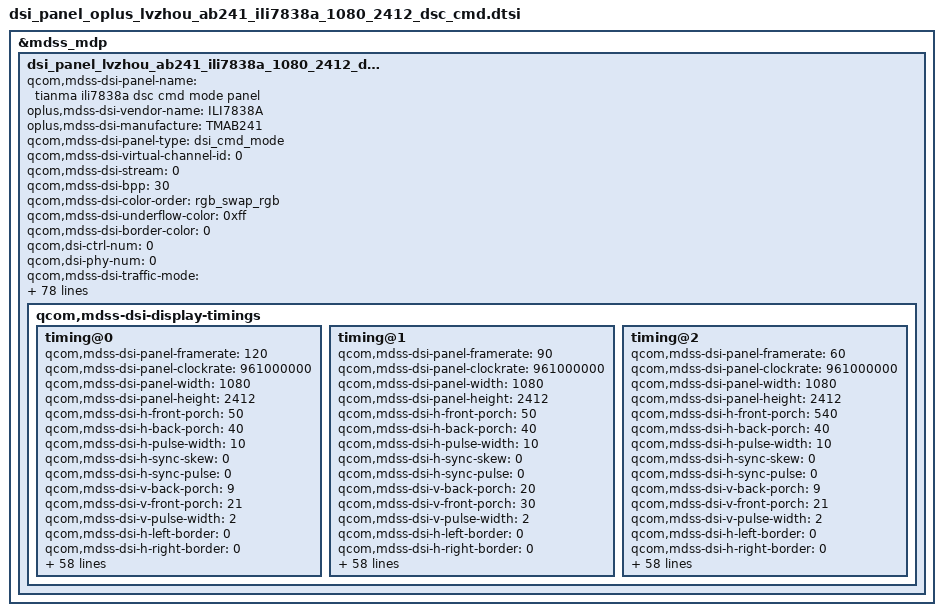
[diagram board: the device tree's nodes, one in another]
&mdss_mdp {
	dsi_panel_lvzhou_ab241_ili7838a_1080_2412_dsc_cmd: qcom,mdss_dsi_panel_lvzhou_ab241_ili7838a_1080_2412_dsc_cmd {
		qcom,mdss-dsi-panel-name = "tianma ili7838a dsc cmd mode panel";
		oplus,mdss-dsi-vendor-name = "ILI7838A";
		oplus,mdss-dsi-manufacture = "TMAB241";
		qcom,mdss-dsi-panel-type = "dsi_cmd_mode";
		qcom,mdss-dsi-virtual-channel-id = <0>;
		qcom,mdss-dsi-stream = <0>;
		qcom,mdss-dsi-bpp = <30>;
		qcom,mdss-dsi-color-order = "rgb_swap_rgb";
		qcom,mdss-dsi-underflow-color = <0xff>;
		qcom,mdss-dsi-border-color = <0>;
		qcom,dsi-ctrl-num = <0>;
		qcom,dsi-phy-num = <0>;
		qcom,mdss-dsi-traffic-mode = "non_burst_sync_event";
		qcom,mdss-dsi-lane-map = "lane_map_0123";
		qcom,mdss-dsi-bllp-eof-power-mode;
		qcom,mdss-dsi-bllp-power-mode;
		qcom,mdss-dsi-lane-0-state;
		qcom,mdss-dsi-lane-1-state;
		qcom,mdss-dsi-lane-2-state;
		qcom,mdss-dsi-lane-3-state;
		qcom,mdss-dsi-dma-trigger = "trigger_sw";
		qcom,mdss-dsi-mdp-trigger = "none";
		qcom,mdss-dsi-reset-sequence = <1 10>, <0 10>, <1 10>;

		qcom,mdss-dsi-te-pin-select = <1>;
		qcom,mdss-dsi-te-dcs-command = <1>;
		qcom,mdss-dsi-te-check-enable;
		qcom,mdss-dsi-te-using-te-pin;
		qcom,mdss-dsi-lp11-init;
		qcom,mdss-dsi-wr-mem-start = <0x2c>;
		qcom,mdss-dsi-wr-mem-continue = <0x3c>;
		qcom,mdss-dsi-panel-hdr-enabled;
		qcom,mdss-dsi-panel-hdr-color-primaries = <15635 16450 34000 16000 13250 34500 7500 3000>;
		qcom,mdss-dsi-panel-peak-brightness = <5400000>;
		qcom,mdss-dsi-panel-blackness-level = <2000>;
		qcom,mdss-pan-physical-width-dimension = <70>;
		qcom,mdss-pan-physical-height-dimension = <155>;
		qcom,esd-check-enabled;
		qcom,mdss-dsi-panel-status-check-mode = "reg_read";
		qcom,mdss-dsi-panel-status-command = [06 01 00 01 05 00 01 0A];
		qcom,mdss-dsi-panel-status-command-state = "dsi_lp_mode";
		qcom,mdss-dsi-panel-status-value = <0x9C>;
		qcom,mdss-dsi-panel-status-read-length = <1>;
		qcom,dynamic-mode-switch-enabled;
		qcom,dynamic-mode-switch-type = "dynamic-resolution-switch-immediate";
		qcom,mdss-dsi-display-timings {
			timing@0 {
				qcom,mdss-dsi-panel-framerate = <120>;
				qcom,mdss-dsi-panel-clockrate = <961000000>;
				qcom,mdss-dsi-panel-width = <1080>;
				qcom,mdss-dsi-panel-height = <2412>;
				qcom,mdss-dsi-h-front-porch = <50>;
				qcom,mdss-dsi-h-back-porch = <40>;
				qcom,mdss-dsi-h-pulse-width = <10>;
				qcom,mdss-dsi-h-sync-skew = <0>;
				qcom,mdss-dsi-h-sync-pulse = <0>;
				qcom,mdss-dsi-v-back-porch = <9>;
				qcom,mdss-dsi-v-front-porch = <21>;
				qcom,mdss-dsi-v-pulse-width = <2>;
				qcom,mdss-dsi-h-left-border = <0>;
				qcom,mdss-dsi-h-right-border = <0>;
				qcom,mdss-dsi-v-top-border = <0>;
				qcom,mdss-dsi-v-bottom-border = <0>;
				qcom,mdss-dsi-panel-jitter = <0x4 0x1>;

				oplus,fod-on-vblank = <0>;
				oplus,fod-off-vblank = <3>;
				qcom,mdss-dsi-timing-switch-command = [
					//120HZ
					39 01 00 00 00 00 04 FF 78 38 02
					39 01 00 00 00 00 02 38 11
					39 01 00 00 00 00 04 FF 78 38 00
				];
				qcom,mdss-dsi-on-command = [
					//APL Peak Luminance ON
					39 01 00 00 00 00 04 FF 78 38 0B
					39 01 00 00 00 00 02 17 F3
					39 01 00 00 00 00 02 18 F3
					39 01 00 00 00 00 02 19 F3
					39 01 00 00 00 00 02 1A F3
					39 01 00 00 00 00 02 1B F3
					39 01 00 00 00 00 02 1C F3
					39 01 00 00 00 00 02 1D F3
					39 01 00 00 00 00 04 FF 78 38 0A
					39 01 00 00 00 00 02 37 4F
					39 01 00 00 00 00 02 38 70
					39 01 00 00 00 00 04 FF 78 38 00
					39 01 00 00 00 00 02 55 03

					//R Corner Control off
					39 01 00 00 00 00 04 FF 78 38 17
					39 01 00 00 00 00 02 20 00

					//NVM Reload
					39 01 00 00 00 00 04 FF 78 38 08
					39 01 00 00 00 00 02 45 4C

					////spr 优化
					39 01 00 00 00 00 04 FF 78 38 14
					39 01 00 00 00 00 09 12 00 00 40 40 00 00 00 00
					39 01 00 00 00 00 09 16 00 00 80 00 00 00 00 00
					39 01 00 00 00 00 13 20 40 80 00 00 80 40 00 00 00 00 80 40 40 80 00 00 00 00
					39 01 00 00 00 00 09 22 00 00 00 04 04 00 60 80
					39 01 00 00 00 00 04 FF 78 38 15

					39 01 00 00 00 00 43 00 00
					00 02 00 02 10 03 00 04 00
					05 00 05 10 06 00 06 10 07
					02 08 0d 09 1a 0b 0b 0e 19
					12 19 17 09 1c 0c 21 1e 28
					02 2e 17 35 1e 3d 1c 46 09
					4f 06 58 18 6d 16 79 07 85
					0d 9f 01 bb 0e da 0c fb 1d
					00 0a

					39 01 00 00 00 00 43 50 00
					00 04 00 08 00 0c 00 10 00
					14 00 18 00 1c 00 24 00 2c
					00 30 02 31 00 34 03 39 0f
					3f 01 43 0c 48 01 4f 0e 56
					0d 5d 03 68 09 72 0a 7b 0b
					84 01 93 02 a0 08 ac 0a b7
					0e cc 02 de 04 ee 0b fd 0f
					ff 0c

					39 01 00 00 00 00 04 FF 78 38 0E
					39 01 00 00 00 00 13 38 40 80 00 00 80 40 00 00 00 00 80 40 40 80 00 00 00 00
					//backlight time
					39 01 00 00 00 00 04 FF 78 38 0C
					39 01 00 00 00 00 02 BD C4
					//60HZ
					39 01 00 00 00 00 04 FF 78 38 02
					39 01 00 00 00 00 02 38 11

					//dsc 8bit
					39 01 00 00 00 00 04 FF 78 38 07
					39 01 00 00 00 00 02 29 01

					39 01 00 00 00 00 64 20 00
					00 00 00 00 11 00 00 89 30
					80 09 6c 04 38 00 0c 02 1c
					02 1c 02 00 02 0e 00 20 01
					1f 00 07 00 0c 08 bb 08 7a
					18 00 10 f0 03 0c 20 00 06
					0b 0b 33 0e 1c 2a 38 46 54
					62 69 70 77 79 7b 7d 7e 01
					02 01 00 09 40 09 be 19 fc
					19 fa 19 f8 1a 38 1a 78 1a
					b6 2a f6 2b 34 2b 74 3b 74
					6b f4 00 00 00 00 00 00

					//demura Reload NG 强制demura on
					39 01 00 00 00 00 04 FF 78 38 19
					39 01 00 00 00 00 02 E0 88
					39 01 00 00 00 00 04 FF 78 38 02
					39 01 00 00 00 00 02 32 79
					39 01 00 00 00 00 02 34 79
					39 01 00 00 00 00 02 36 79
					39 01 00 00 00 00 04 FF 78 38 08
					39 01 00 00 00 00 02 96 3F
					39 01 00 00 00 00 02 B0 81
					39 01 00 00 00 00 04 FF 78 38 06
					39 01 00 00 00 00 02 C9 A0

					//IR IP ON
					39 01 00 00 00 00 04 FF 78 38 00
					39 01 00 00 00 00 02 95 10

					//TE ON
					39 01 00 00 00 00 04 FF 78 38 00
					39 01 00 00 00 00 02 35 00

					//Dimming Setting
					39 01 00 00 00 00 02 53 20
					39 01 00 00 00 00 03 51 0D BB

					//Sleep out
					05 01 00 00 79 00 01 11
					05 01 00 00 00 00 01 29
				];
				qcom,mdss-dsi-off-command= [
					05 01 00 00 0B 00 01 28
					05 01 00 00 79 00 01 10];
				qcom,mdss-dsi-post-on-backlight = [
					/* Display On */

				];
				qcom,mdss-dsi-hbm-on-command = [
					//hbm
					39 01 00 00 11 00 02 53 20
					39 01 00 00 00 00 03 51 0F FF
				];
				qcom,mdss-dsi-normal-hbm-on-command = [
					//hbm
					39 01 00 00 11 00 02 53 20
					39 01 00 00 00 00 03 51 0F FF
				];
				qcom,mdss-dsi-hbm-off-command = [
					39 01 00 00 02 00 02 53 20
				];
				qcom,mdss-dsi-aod-hbm-on-command = [

				];
				qcom,mdss-dsi-aod-hbm-off-command = [

				];
				qcom,mdss-dsi-aod-high-mode-command = [
					39 01 00 00 00 00 04 FF 78 38 00
					39 01 00 00 00 00 02 39 00
					39 01 00 00 00 00 04 FF 78 38 0C
					39 01 00 00 00 00 02 BE 01
				];
				qcom,mdss-dsi-aod-low-mode-command = [
					39 01 00 00 00 00 04 FF 78 38 00
					39 01 00 00 00 00 02 39 00
					39 01 00 00 00 00 04 FF 78 38 0C
					39 01 00 00 00 00 02 BE 00
				];
				qcom,mdss-dsi-lp1-command = [
					//AOD ON
					39 01 00 00 00 00 04 FF 78 38 00
					39 01 00 00 00 00 02 39 00
					39 01 00 00 00 00 04 FF 78 38 0C
					39 01 00 00 00 00 02 BE 01
				];
				qcom,mdss-dsi-nolp-command = [
					//AOD OFF
					39 01 00 00 00 00 04 FF 78 38 00
					39 01 00 00 00 00 02 38 00
				];
				//qcom,mdss-dsi-seed-off-command = [

				//];
				//qcom,mdss-dsi-seed-3-command = [

				//];
				//qcom,mdss-dsi-seed-2-command = [

				//];
				//qcom,mdss-dsi-seed-1-command = [

				//];
				//qcom,mdss-dsi-seed-0-command = [

				//];
				qcom,mdss-dsi-hbm-enter-switch-command = [
					39 01 00 00 00 00 03 51 0D BB
				];
				qcom,mdss-dsi-hbm-exit-switch-command = [
					39 01 00 00 00 00 03 51 0D BB
				];
				qcom,mdss-dsi-osc-clk-mode0-command = [

				];
				qcom,mdss-dsi-osc-clk-mode1-command = [

				];
				qcom,mdss-dsi-timing-switch-command-state = "dsi_hs_mode";
				qcom,mdss-dsi-on-command-state = "dsi_lp_mode";
				qcom,mdss-dsi-off-command-state = "dsi_hs_mode";
				qcom,mdss-dsi-hbm-on-command-state = "dsi_hs_mode";
				qcom,mdss-dsi-hbm-off-command-state = "dsi_hs_mode";
				qcom,mdss-dsi-osc-clk-mode0-command-state = "dsi_hs_mode";
				qcom,mdss-dsi-osc-clk-mode1-command-state = "dsi_hs_mode";
				//qcom,mdss-dsi-seed-0-command-state = "dsi_hs_mode";
				//qcom,mdss-dsi-seed-1-command-state = "dsi_hs_mode";
				//qcom,mdss-dsi-seed-2-command-state = "dsi_hs_mode";
				//qcom,mdss-dsi-seed-3-command-state = "dsi_hs_mode";
				//qcom,mdss-dsi-seed-off-command-state = "dsi_hs_mode";
				qcom,compression-mode = "dsc";
				qcom,mdss-dsc-slice-height = <12>;
				qcom,mdss-dsc-slice-width = <540>;
				qcom,mdss-dsc-slice-per-pkt = <2>;
				qcom,mdss-dsc-bit-per-component = <8>;
				qcom,mdss-dsc-bit-per-pixel = <8>;
				qcom,mdss-dsc-block-prediction-enable;
				qcom,mdss-dsc-version = <0x11>;
			};
			timing@1 {
				qcom,mdss-dsi-panel-framerate = <90>;
				qcom,mdss-dsi-panel-clockrate = <961000000>;
				qcom,mdss-dsi-panel-width = <1080>;
				qcom,mdss-dsi-panel-height = <2412>;
				qcom,mdss-dsi-h-front-porch = <50>;
				qcom,mdss-dsi-h-back-porch = <40>;
				qcom,mdss-dsi-h-pulse-width = <10>;
				qcom,mdss-dsi-h-sync-skew = <0>;
				qcom,mdss-dsi-h-sync-pulse = <0>;
				qcom,mdss-dsi-v-back-porch = <20>;
				qcom,mdss-dsi-v-front-porch = <30>;
				qcom,mdss-dsi-v-pulse-width = <2>;
				qcom,mdss-dsi-h-left-border = <0>;
				qcom,mdss-dsi-h-right-border = <0>;
				qcom,mdss-dsi-v-top-border = <0>;
				qcom,mdss-dsi-v-bottom-border = <0>;
				qcom,mdss-dsi-panel-jitter = <0x4 0x1>;

				oplus,fod-on-vblank = <0>;
				oplus,fod-off-vblank = <3>;
				qcom,mdss-dsi-timing-switch-command = [
					//90HZ
					39 01 00 00 00 00 04 FF 78 38 02
					39 01 00 00 00 00 02 38 12
					39 01 00 00 00 00 04 FF 78 38 00
				];
				qcom,mdss-dsi-on-command = [
					//APL Peak Luminance ON
					39 01 00 00 00 00 04 FF 78 38 0B
					39 01 00 00 00 00 02 17 F3
					39 01 00 00 00 00 02 18 F3
					39 01 00 00 00 00 02 19 F3
					39 01 00 00 00 00 02 1A F3
					39 01 00 00 00 00 02 1B F3
					39 01 00 00 00 00 02 1C F3
					39 01 00 00 00 00 02 1D F3
					39 01 00 00 00 00 04 FF 78 38 0A
					39 01 00 00 00 00 02 37 4F
					39 01 00 00 00 00 02 38 70
					39 01 00 00 00 00 04 FF 78 38 00
					39 01 00 00 00 00 02 55 03

					//R Corner Control off
					39 01 00 00 00 00 04 FF 78 38 17
					39 01 00 00 00 00 02 20 00

					//NVM Reload
					39 01 00 00 00 00 04 FF 78 38 08
					39 01 00 00 00 00 02 45 4C

					////spr 优化
					39 01 00 00 00 00 04 FF 78 38 14
					39 01 00 00 00 00 09 12 00 00 40 40 00 00 00 00
					39 01 00 00 00 00 09 16 00 00 80 00 00 00 00 00
					39 01 00 00 00 00 13 20 40 80 00 00 80 40 00 00 00 00 80 40 40 80 00 00 00 00
					39 01 00 00 00 00 09 22 00 00 00 04 04 00 60 80
					39 01 00 00 00 00 04 FF 78 38 15

					39 01 00 00 00 00 43 00 00
					00 02 00 02 10 03 00 04 00
					05 00 05 10 06 00 06 10 07
					02 08 0d 09 1a 0b 0b 0e 19
					12 19 17 09 1c 0c 21 1e 28
					02 2e 17 35 1e 3d 1c 46 09
					4f 06 58 18 6d 16 79 07 85
					0d 9f 01 bb 0e da 0c fb 1d
					00 0a

					39 01 00 00 00 00 43 50 00
					00 04 00 08 00 0c 00 10 00
					14 00 18 00 1c 00 24 00 2c
					00 30 02 31 00 34 03 39 0f
					3f 01 43 0c 48 01 4f 0e 56
					0d 5d 03 68 09 72 0a 7b 0b
					84 01 93 02 a0 08 ac 0a b7
					0e cc 02 de 04 ee 0b fd 0f
					ff 0c

					39 01 00 00 00 00 04 FF 78 38 0E
					39 01 00 00 00 00 13 38 40 80 00 00 80 40 00 00 00 00 80 40 40 80 00 00 00 00
					//backlight time
					39 01 00 00 00 00 04 FF 78 38 0C
					39 01 00 00 00 00 02 BD C4
					//60HZ
					39 01 00 00 00 00 04 FF 78 38 02
					39 01 00 00 00 00 02 38 12

					//dsc 8bit
					39 01 00 00 00 00 04 FF 78 38 07
					39 01 00 00 00 00 02 29 01

					39 01 00 00 00 00 64 20 00
					00 00 00 00 11 00 00 89 30
					80 09 6c 04 38 00 0c 02 1c
					02 1c 02 00 02 0e 00 20 01
					1f 00 07 00 0c 08 bb 08 7a
					18 00 10 f0 03 0c 20 00 06
					0b 0b 33 0e 1c 2a 38 46 54
					62 69 70 77 79 7b 7d 7e 01
					02 01 00 09 40 09 be 19 fc
					19 fa 19 f8 1a 38 1a 78 1a
					b6 2a f6 2b 34 2b 74 3b 74
					6b f4 00 00 00 00 00 00

					//demura Reload NG 强制demura on
					39 01 00 00 00 00 04 FF 78 38 19
					39 01 00 00 00 00 02 E0 88
					39 01 00 00 00 00 04 FF 78 38 02
					39 01 00 00 00 00 02 32 79
					39 01 00 00 00 00 02 34 79
					39 01 00 00 00 00 02 36 79
					39 01 00 00 00 00 04 FF 78 38 08
					39 01 00 00 00 00 02 96 3F
					39 01 00 00 00 00 02 B0 81
					39 01 00 00 00 00 04 FF 78 38 06
					39 01 00 00 00 00 02 C9 A0

					//IR IP ON
					39 01 00 00 00 00 04 FF 78 38 00
					39 01 00 00 00 00 02 95 10

					//TE ON
					39 01 00 00 00 00 04 FF 78 38 00
					39 01 00 00 00 00 02 35 00

					//Dimming Setting
					39 01 00 00 00 00 02 53 20
					39 01 00 00 00 00 03 51 0D BB

					//Sleep out
					05 01 00 00 79 00 01 11
					05 01 00 00 00 00 01 29
				];
				qcom,mdss-dsi-off-command= [
					05 01 00 00 0B 00 01 28
					05 01 00 00 79 00 01 10];
				qcom,mdss-dsi-post-on-backlight = [
					/* Display On */

				];
				qcom,mdss-dsi-hbm-on-command = [
					//hbm
					39 01 00 00 11 00 02 53 20
					39 01 00 00 00 00 03 51 0F FF
				];
				qcom,mdss-dsi-normal-hbm-on-command = [
					//hbm
					39 01 00 00 11 00 02 53 20
					39 01 00 00 00 00 03 51 0F FF
				];
				qcom,mdss-dsi-hbm-off-command = [
					39 01 00 00 02 00 02 53 20
				];
				qcom,mdss-dsi-aod-hbm-on-command = [

				];
				qcom,mdss-dsi-aod-hbm-off-command = [

				];
				qcom,mdss-dsi-aod-high-mode-command = [
					39 01 00 00 00 00 04 FF 78 38 00
					39 01 00 00 00 00 02 39 00
					39 01 00 00 00 00 04 FF 78 38 0C
					39 01 00 00 00 00 02 BE 01
				];
				qcom,mdss-dsi-aod-low-mode-command = [
					39 01 00 00 00 00 04 FF 78 38 00
					39 01 00 00 00 00 02 39 00
					39 01 00 00 00 00 04 FF 78 38 0C
					39 01 00 00 00 00 02 BE 00
				];
				qcom,mdss-dsi-lp1-command = [
					//AOD ON
					39 01 00 00 00 00 04 FF 78 38 00
					39 01 00 00 00 00 02 39 00
					39 01 00 00 00 00 04 FF 78 38 0C
					39 01 00 00 00 00 02 BE 01
				];
				qcom,mdss-dsi-nolp-command = [
					//AOD OFF
					39 01 00 00 00 00 04 FF 78 38 00
					39 01 00 00 00 00 02 38 00
				];
				qcom,mdss-dsi-hbm-enter-switch-command = [
					39 01 00 00 00 00 03 51 0D BB
				];
				qcom,mdss-dsi-hbm-exit-switch-command = [
					39 01 00 00 00 00 03 51 0D BB
				];
				qcom,mdss-dsi-osc-clk-mode0-command = [

				];
				qcom,mdss-dsi-osc-clk-mode1-command = [

				];
				qcom,mdss-dsi-timing-switch-command-state = "dsi_hs_mode";
				qcom,mdss-dsi-on-command-state = "dsi_lp_mode";
				qcom,mdss-dsi-off-command-state = "dsi_hs_mode";
				qcom,mdss-dsi-hbm-on-command-state = "dsi_hs_mode";
				qcom,mdss-dsi-hbm-off-command-state = "dsi_hs_mode";
				qcom,mdss-dsi-osc-clk-mode0-command-state = "dsi_hs_mode";
				qcom,mdss-dsi-osc-clk-mode1-command-state = "dsi_hs_mode";
				qcom,compression-mode = "dsc";
				qcom,mdss-dsc-slice-height = <12>;
				qcom,mdss-dsc-slice-width = <540>;
				qcom,mdss-dsc-slice-per-pkt = <2>;
				qcom,mdss-dsc-bit-per-component = <8>;
				qcom,mdss-dsc-bit-per-pixel = <8>;
				qcom,mdss-dsc-block-prediction-enable;
				qcom,mdss-dsc-version = <0x11>;
			};
			timing@2 {
				qcom,mdss-dsi-panel-framerate = <60>;
				qcom,mdss-dsi-panel-clockrate = <961000000>;
				qcom,mdss-dsi-panel-width = <1080>;
				qcom,mdss-dsi-panel-height = <2412>;
				qcom,mdss-dsi-h-front-porch = <540>;
				qcom,mdss-dsi-h-back-porch = <40>;
				qcom,mdss-dsi-h-pulse-width = <10>;
				qcom,mdss-dsi-h-sync-skew = <0>;
				qcom,mdss-dsi-h-sync-pulse = <0>;
				qcom,mdss-dsi-v-back-porch = <9>;
				qcom,mdss-dsi-v-front-porch = <21>;
				qcom,mdss-dsi-v-pulse-width = <2>;
				qcom,mdss-dsi-h-left-border = <0>;
				qcom,mdss-dsi-h-right-border = <0>;
				qcom,mdss-dsi-v-top-border = <0>;
				qcom,mdss-dsi-v-bottom-border = <0>;
				qcom,mdss-dsi-panel-jitter = <0x4 0x1>;

				oplus,fod-on-vblank = <0>;
				oplus,fod-off-vblank = <3>;
				qcom,mdss-dsi-timing-switch-command = [
					//60HZ
					39 01 00 00 00 00 04 FF 78 38 02
					39 01 00 00 00 00 02 38 13
					39 01 00 00 00 00 04 FF 78 38 00
				];
				qcom,mdss-dsi-on-command = [
					//APL Peak Luminance ON
					39 01 00 00 00 00 04 FF 78 38 0B
					39 01 00 00 00 00 02 17 F3
					39 01 00 00 00 00 02 18 F3
					39 01 00 00 00 00 02 19 F3
					39 01 00 00 00 00 02 1A F3
					39 01 00 00 00 00 02 1B F3
					39 01 00 00 00 00 02 1C F3
					39 01 00 00 00 00 02 1D F3
					39 01 00 00 00 00 04 FF 78 38 0A
					39 01 00 00 00 00 02 37 4F
					39 01 00 00 00 00 02 38 70
					39 01 00 00 00 00 04 FF 78 38 00
					39 01 00 00 00 00 02 55 03

					//R Corner Control off
					39 01 00 00 00 00 04 FF 78 38 17
					39 01 00 00 00 00 02 20 00

					//NVM Reload
					39 01 00 00 00 00 04 FF 78 38 08
					39 01 00 00 00 00 02 45 4C

					////spr 优化
					39 01 00 00 00 00 04 FF 78 38 14
					39 01 00 00 00 00 09 12 00 00 40 40 00 00 00 00
					39 01 00 00 00 00 09 16 00 00 80 00 00 00 00 00
					39 01 00 00 00 00 13 20 40 80 00 00 80 40 00 00 00 00 80 40 40 80 00 00 00 00
					39 01 00 00 00 00 09 22 00 00 00 04 04 00 60 80
					39 01 00 00 00 00 04 FF 78 38 15

					39 01 00 00 00 00 43 00 00
					00 02 00 02 10 03 00 04 00
					05 00 05 10 06 00 06 10 07
					02 08 0d 09 1a 0b 0b 0e 19
					12 19 17 09 1c 0c 21 1e 28
					02 2e 17 35 1e 3d 1c 46 09
					4f 06 58 18 6d 16 79 07 85
					0d 9f 01 bb 0e da 0c fb 1d
					00 0a

					39 01 00 00 00 00 43 50 00
					00 04 00 08 00 0c 00 10 00
					14 00 18 00 1c 00 24 00 2c
					00 30 02 31 00 34 03 39 0f
					3f 01 43 0c 48 01 4f 0e 56
					0d 5d 03 68 09 72 0a 7b 0b
					84 01 93 02 a0 08 ac 0a b7
					0e cc 02 de 04 ee 0b fd 0f
					ff 0c

					39 01 00 00 00 00 04 FF 78 38 0E
					39 01 00 00 00 00 13 38 40 80 00 00 80 40 00 00 00 00 80 40 40 80 00 00 00 00
					//backlight time
					39 01 00 00 00 00 04 FF 78 38 0C
					39 01 00 00 00 00 02 BD C4
					//60HZ
					39 01 00 00 00 00 04 FF 78 38 02
					39 01 00 00 00 00 02 38 13

					//dsc 8bit
					39 01 00 00 00 00 04 FF 78 38 07
					39 01 00 00 00 00 02 29 01

					39 01 00 00 00 00 64 20 00
					00 00 00 00 11 00 00 89 30
					80 09 6c 04 38 00 0c 02 1c
					02 1c 02 00 02 0e 00 20 01
					1f 00 07 00 0c 08 bb 08 7a
					18 00 10 f0 03 0c 20 00 06
					0b 0b 33 0e 1c 2a 38 46 54
					62 69 70 77 79 7b 7d 7e 01
					02 01 00 09 40 09 be 19 fc
					19 fa 19 f8 1a 38 1a 78 1a
					b6 2a f6 2b 34 2b 74 3b 74
					6b f4 00 00 00 00 00 00

					//demura Reload NG 强制demura on
					39 01 00 00 00 00 04 FF 78 38 19
					39 01 00 00 00 00 02 E0 88
					39 01 00 00 00 00 04 FF 78 38 02
					39 01 00 00 00 00 02 32 79
					39 01 00 00 00 00 02 34 79
					39 01 00 00 00 00 02 36 79
					39 01 00 00 00 00 04 FF 78 38 08
					39 01 00 00 00 00 02 96 3F
					39 01 00 00 00 00 02 B0 81
					39 01 00 00 00 00 04 FF 78 38 06
					39 01 00 00 00 00 02 C9 A0

					//IR IP ON
					39 01 00 00 00 00 04 FF 78 38 00
					39 01 00 00 00 00 02 95 10

					//TE ON
					39 01 00 00 00 00 04 FF 78 38 00
					39 01 00 00 00 00 02 35 00

					//Dimming Setting
					39 01 00 00 00 00 02 53 20

					//Sleep out
					05 01 00 00 79 00 01 11
					05 01 00 00 00 00 01 29
				];
				qcom,mdss-dsi-off-command= [
					05 01 00 00 0B 00 01 28
					05 01 00 00 79 00 01 10];
				qcom,mdss-dsi-post-on-backlight = [
					/* Display On */

				];
				qcom,mdss-dsi-hbm-on-command = [
					//hbm
					39 01 00 00 11 00 02 53 20
					39 01 00 00 00 00 03 51 0F FF
				];
				qcom,mdss-dsi-normal-hbm-on-command = [
					//hbm
					39 01 00 00 11 00 02 53 20
					39 01 00 00 00 00 03 51 0F FF
				];
				qcom,mdss-dsi-hbm-off-command = [
					39 01 00 00 02 00 02 53 20
				];
				qcom,mdss-dsi-aod-hbm-on-command = [

				];
				qcom,mdss-dsi-aod-hbm-off-command = [

				];
				qcom,mdss-dsi-aod-high-mode-command = [
					39 01 00 00 00 00 04 FF 78 38 00
					39 01 00 00 00 00 02 39 00
					39 01 00 00 00 00 04 FF 78 38 0C
					39 01 00 00 00 00 02 BE 01
				];
				qcom,mdss-dsi-aod-low-mode-command = [
					39 01 00 00 00 00 04 FF 78 38 00
					39 01 00 00 00 00 02 39 00
					39 01 00 00 00 00 04 FF 78 38 0C
					39 01 00 00 00 00 02 BE 00
				];
				qcom,mdss-dsi-lp1-command = [
					//AOD ON
					39 01 00 00 00 00 04 FF 78 38 00
					39 01 00 00 00 00 02 39 00
					39 01 00 00 00 00 04 FF 78 38 0C
					39 01 00 00 00 00 02 BE 01
				];
				qcom,mdss-dsi-nolp-command = [
					//AOD OFF
					39 01 00 00 00 00 04 FF 78 38 00
					39 01 00 00 00 00 02 38 00
				];
				//qcom,mdss-dsi-seed-off-command = [

				//];
				//qcom,mdss-dsi-seed-3-command = [

				//];
				//qcom,mdss-dsi-seed-2-command = [

				//];
				//qcom,mdss-dsi-seed-1-command = [

				//];
				//qcom,mdss-dsi-seed-0-command = [

				//];
				qcom,mdss-dsi-hbm-enter-switch-command = [
					39 01 00 00 00 00 03 51 0D BB
				];
				qcom,mdss-dsi-hbm-exit-switch-command = [
					39 01 00 00 00 00 03 51 0D BB
				];
				qcom,mdss-dsi-osc-clk-mode0-command = [

				];
				qcom,mdss-dsi-osc-clk-mode1-command = [

				];

				qcom,mdss-dsi-timing-switch-command-state = "dsi_hs_mode";
				qcom,mdss-dsi-on-command-state = "dsi_lp_mode";
				qcom,mdss-dsi-off-command-state = "dsi_hs_mode";
				qcom,mdss-dsi-hbm-on-command-state = "dsi_hs_mode";
				qcom,mdss-dsi-hbm-off-command-state = "dsi_hs_mode";
				qcom,mdss-dsi-osc-clk-mode0-command-state = "dsi_hs_mode";
				qcom,mdss-dsi-osc-clk-mode1-command-state = "dsi_hs_mode";
				//qcom,mdss-dsi-seed-0-command-state = "dsi_hs_mode";
				//qcom,mdss-dsi-seed-1-command-state = "dsi_hs_mode";
				//qcom,mdss-dsi-seed-2-command-state = "dsi_hs_mode";
				//qcom,mdss-dsi-seed-3-command-state = "dsi_hs_mode";
				//qcom,mdss-dsi-seed-off-command-state = "dsi_hs_mode";
				qcom,compression-mode = "dsc";
				qcom,mdss-dsc-slice-height = <12>;
				qcom,mdss-dsc-slice-width = <540>;
				qcom,mdss-dsc-slice-per-pkt = <2>;
				qcom,mdss-dsc-bit-per-component = <8>;
				qcom,mdss-dsc-bit-per-pixel = <8>;
				qcom,mdss-dsc-block-prediction-enable;
				qcom,mdss-dsc-version = <0x11>;
			};
		};
	};
};



&dsi_panel_lvzhou_ab241_ili7838a_1080_2412_dsc_cmd {
	qcom,panel-supply-entries = <&dsi_panel_oplus_optimization_pwr_supply_lvzhou>;
	qcom,mdss-dsi-panel-controller = <&mdss_dsi0>;
	qcom,mdss-dsi-bl-pmic-control-type = "bl_ctrl_dcs";
	qcom,mdss-dsi-bl-inverted-dbv;
	qcom,mdss-dsi-bl-min-level = <1>;
	qcom,mdss-dsi-bl-max-level = <4095>;
	qcom,mdss-brightness-max-level = <4095>;
	oplus,dsi-bl-normal-max-level = <3515>;
	oplus,dsi-brightness-normal-max-level = <3515>;
	oplus,dsi-brightness-default-level = <400>;
	qcom,platform-te-gpio = <&tlmm 86 0>;
	qcom,platform-reset-gpio = <&tlmm 3 0>;
	qcom,ulps-enabled;
	qcom,dsi-select-clocks = "pll_byte_clk0", "pll_dsi_clk0";

	oplus,dsi-fod-brightness = <36 0xed>,
			<60 0xec>,
			<90 0xeb>,
			<140 0xea>,
			<200 0xe8>,
			<300 0xe4>,
			<458 0xe0>,
			<605 0xdb>,
			<743 0xcf>,
			<912 0xc8>,
			<1062 0xbf>,
			<1187 0xb6>,
			<1393 0xa0>,
			<1611 0x9b>,
			<1787 0x92>,
			<2000 0x8b>,
			<2200 0x80>,
			<2400 0x70>,
			<2600 0x60>,
			<2800 0x50>,
			<3000 0x4A>,
			<3200 0x40>,
			<3400 0x36>,
			<3515 0x2e>;
	oplus,dsi-dc-brightness = <0 0xff>,
			<2 0xFC>,
			<4 0xF9>,
			<6 0xF9>,
			<8 0xF8>,
			<10 0xF7>,
			<15 0xF6>,
			<20 0xF4>,
			<30 0xF0>,
			<40 0xEB>,
			<50 0xE6>,
			<60 0xE1>,
			<70 0xDD>,
			<80 0xD8>,
			<100 0xCF>,
			<120 0xC5>,
			<150 0xB9>,
			<200 0xA2>,
			<250 0x8C>,
			<300 0x76>,
			<350 0x5B>,
			<400 0x44>,
			<450 0x2C>,
			<500 0x0D>,
			<520 0x00>;

	qcom,mdss-dsi-display-timings {
		timing@0 {
				qcom,mdss-dsi-panel-phy-timings = [00 21 08 08 19 22 09 08 09 02 04 00 1C 0D];
				qcom,display-topology = <1 1 1>,<2 2 1>;
				qcom,default-topology-index = <0>;
		};
		timing@1 {
				qcom,mdss-dsi-panel-phy-timings = [00 21 08 08 19 22 09 08 09 02 04 00 1C 0D];
				qcom,display-topology = <1 1 1>,<2 2 1>;
				qcom,default-topology-index = <0>;
		};
		timing@2 {
				qcom,mdss-dsi-panel-phy-timings = [00 21 08 08 19 22 09 08 09 02 04 00 1C 0D];
				qcom,display-topology = <1 1 1>,<2 2 1>;
				qcom,default-topology-index = <0>;
		};
	};
};

&dsi_panel_lvzhou_ab241_ili7838a_1080_2412_dsc_cmd {
	oplus,color_vivid_status;
	oplus,color_srgb_status;
	oplus,color_softiris_status;
	oplus,color_dual_brightness_status;
};

&dsi_panel_lvzhou_ab241_ili7838a_1080_2412_dsc_cmd {
	qcom,panel_voltage_vddi_name = "vddio";
	qcom,panel_voltage_vddi = <0 1800000 1850000 1950000>;
	qcom,panel_voltage_vddr_name = "vddio";
	qcom,panel_voltage_vddr = <1 1800000 1850000 1950000>;
};
